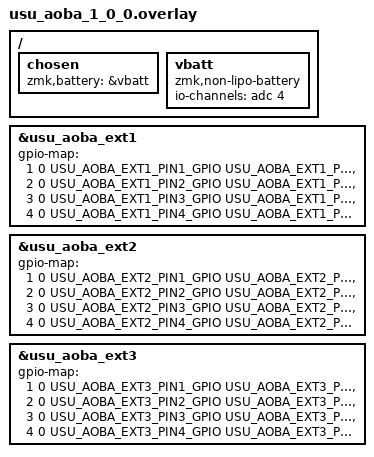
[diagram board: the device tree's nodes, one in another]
/* Extension connector 1, pins 1 through 4. */
#define USU_AOBA_EXT1_PIN1_GPIO &gpio0
#define USU_AOBA_EXT1_PIN1_PORT 0
#define USU_AOBA_EXT1_PIN1_NUMBER 23
#define USU_AOBA_EXT1_PIN2_GPIO &gpio0
#define USU_AOBA_EXT1_PIN2_PORT 0
#define USU_AOBA_EXT1_PIN2_NUMBER 21
#define USU_AOBA_EXT1_PIN3_GPIO &gpio1
#define USU_AOBA_EXT1_PIN3_PORT 1
#define USU_AOBA_EXT1_PIN3_NUMBER 14
#define USU_AOBA_EXT1_PIN4_GPIO &gpio0
#define USU_AOBA_EXT1_PIN4_PORT 0
#define USU_AOBA_EXT1_PIN4_NUMBER 3

/* Extension connector 2, pins 1 through 4. */
#define USU_AOBA_EXT2_PIN1_GPIO &gpio0
#define USU_AOBA_EXT2_PIN1_PORT 0
#define USU_AOBA_EXT2_PIN1_NUMBER 5
#define USU_AOBA_EXT2_PIN2_GPIO &gpio0
#define USU_AOBA_EXT2_PIN2_PORT 0
#define USU_AOBA_EXT2_PIN2_NUMBER 4
#define USU_AOBA_EXT2_PIN3_GPIO &gpio1
#define USU_AOBA_EXT2_PIN3_PORT 1
#define USU_AOBA_EXT2_PIN3_NUMBER 8
#define USU_AOBA_EXT2_PIN4_GPIO &gpio0
#define USU_AOBA_EXT2_PIN4_PORT 0
#define USU_AOBA_EXT2_PIN4_NUMBER 7

/* Extension connector 3, pins 1 through 4. */
#define USU_AOBA_EXT3_PIN1_GPIO &gpio0
#define USU_AOBA_EXT3_PIN1_PORT 0
#define USU_AOBA_EXT3_PIN1_NUMBER 11
#define USU_AOBA_EXT3_PIN2_GPIO &gpio0
#define USU_AOBA_EXT3_PIN2_PORT 0
#define USU_AOBA_EXT3_PIN2_NUMBER 16
#define USU_AOBA_EXT3_PIN3_GPIO &gpio0
#define USU_AOBA_EXT3_PIN3_PORT 0
#define USU_AOBA_EXT3_PIN3_NUMBER 14
#define USU_AOBA_EXT3_PIN4_GPIO &gpio0
#define USU_AOBA_EXT3_PIN4_PORT 0
#define USU_AOBA_EXT3_PIN4_NUMBER 19

/ {
	chosen {
		zmk,battery = &vbatt;
	};

	vbatt: vbatt {
		compatible = "zmk,non-lipo-battery";
		io-channels = <&adc 4>;
	};
};

&usu_aoba_ext1 {
	status = "okay";
	gpio-map = <1 0 USU_AOBA_EXT1_PIN1_GPIO USU_AOBA_EXT1_PIN1_NUMBER 0>,
		<2 0 USU_AOBA_EXT1_PIN2_GPIO USU_AOBA_EXT1_PIN2_NUMBER 0>,
		<3 0 USU_AOBA_EXT1_PIN3_GPIO USU_AOBA_EXT1_PIN3_NUMBER 0>,
		<4 0 USU_AOBA_EXT1_PIN4_GPIO USU_AOBA_EXT1_PIN4_NUMBER 0>;
};

&usu_aoba_ext2 {
	status = "okay";
	gpio-map = <1 0 USU_AOBA_EXT2_PIN1_GPIO USU_AOBA_EXT2_PIN1_NUMBER 0>,
		<2 0 USU_AOBA_EXT2_PIN2_GPIO USU_AOBA_EXT2_PIN2_NUMBER 0>,
		<3 0 USU_AOBA_EXT2_PIN3_GPIO USU_AOBA_EXT2_PIN3_NUMBER 0>,
		<4 0 USU_AOBA_EXT2_PIN4_GPIO USU_AOBA_EXT2_PIN4_NUMBER 0>;
};

&usu_aoba_ext3 {
	status = "okay";
	gpio-map = <1 0 USU_AOBA_EXT3_PIN1_GPIO USU_AOBA_EXT3_PIN1_NUMBER 0>,
		<2 0 USU_AOBA_EXT3_PIN2_GPIO USU_AOBA_EXT3_PIN2_NUMBER 0>,
		<3 0 USU_AOBA_EXT3_PIN3_GPIO USU_AOBA_EXT3_PIN3_NUMBER 0>,
		<4 0 USU_AOBA_EXT3_PIN4_GPIO USU_AOBA_EXT3_PIN4_NUMBER 0>;
};
